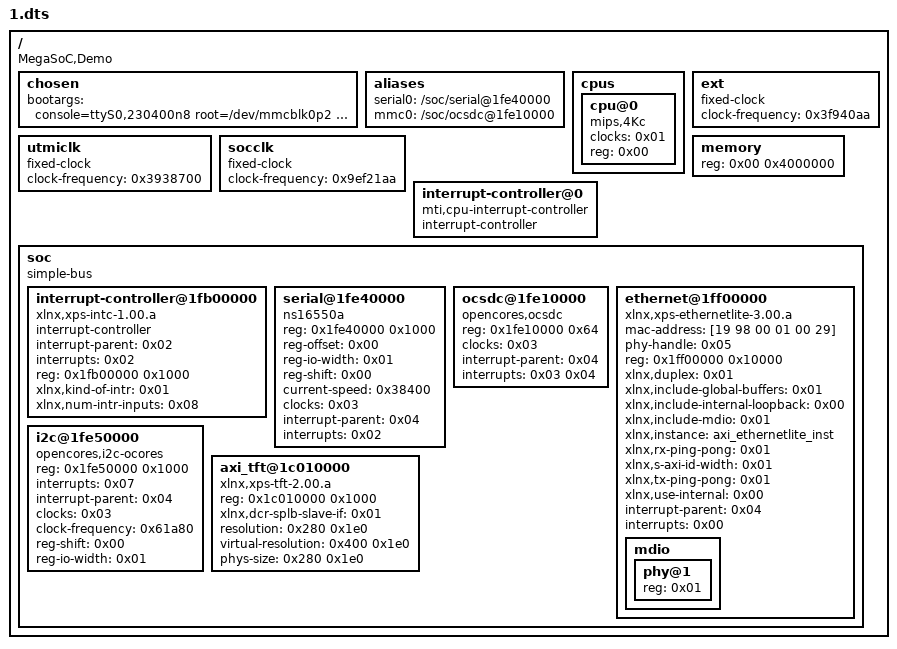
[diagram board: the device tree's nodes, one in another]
/dts-v1/;

/ {
	compatible = "MegaSoC,Demo";
	#address-cells = <0x01>;
	#size-cells = <0x01>;

	chosen {
		bootargs = "console=ttyS0,230400n8 root=/dev/mmcblk0p2 rootfstype=ext4 rw rootwait";
	};

	aliases {
		serial0 = "/soc/serial@1fe40000";
		mmc0 = "/soc/ocsdc@1fe10000";
	};

	cpus {
		#address-cells = <0x01>;
		#size-cells = <0x00>;

		cpu@0 {
			device_type = "cpu";
			compatible = "mips,4Kc";
			clocks = <0x01>;
			reg = <0x00>;
		};
	};

	ext {
		compatible = "fixed-clock";
		clock-frequency = <0x3f940aa>;
		#clock-cells = <0x00>;
		phandle = <0x01>;
	};

	utmiclk {
		compatible = "fixed-clock";
		clock-frequency = <0x3938700>;
		#clock-cells = <0x00>;
	};

	socclk {
		compatible = "fixed-clock";
		clock-frequency = <0x9ef21aa>;
		#clock-cells = <0x00>;
		phandle = <0x03>;
	};

	memory {
		device_type = "memory";
		reg = <0x00 0x4000000>;
	};

	interrupt-controller@0 {
		#address-cells = <0x00>;
		#interrupt-cells = <0x01>;
		interrupt-controller;
		compatible = "mti,cpu-interrupt-controller";
		phandle = <0x02>;
	};

	soc {
		compatible = "simple-bus";
		#address-cells = <0x01>;
		#size-cells = <0x01>;
		#interrupt-cells = <0x01>;
		ranges;

		interrupt-controller@1fb00000 {
			#interrupt-cells = <0x01>;
			compatible = "xlnx,xps-intc-1.00.a";
			interrupt-controller;
			interrupt-parent = <0x02>;
			interrupts = <0x02>;
			reg = <0x1fb00000 0x1000>;
			xlnx,kind-of-intr = <0x01>;
			xlnx,num-intr-inputs = <0x08>;
			phandle = <0x04>;
		};

		serial@1fe40000 {
			device_type = "serial";
			compatible = "ns16550a";
			reg = <0x1fe40000 0x1000>;
			reg-offset = <0x00>;
			reg-io-width = <0x01>;
			reg-shift = <0x00>;
			current-speed = <0x38400>;
			clocks = <0x03>;
			interrupt-parent = <0x04>;
			interrupts = <0x02>;
		};

		ocsdc@1fe10000 {
			compatible = "opencores,ocsdc";
			reg = <0x1fe10000 0x64>;
			clocks = <0x03>;
			interrupt-parent = <0x04>;
			interrupts = <0x03 0x04>;
		};

		ethernet@1ff00000 {
			compatible = "xlnx,xps-ethernetlite-3.00.a";
			device_type = "network";
			mac-address = [19 98 00 01 00 29];
			phy-handle = <0x05>;
			reg = <0x1ff00000 0x10000>;
			xlnx,duplex = <0x01>;
			xlnx,include-global-buffers = <0x01>;
			xlnx,include-internal-loopback = <0x00>;
			xlnx,include-mdio = <0x01>;
			xlnx,instance = "axi_ethernetlite_inst";
			xlnx,rx-ping-pong = <0x01>;
			xlnx,s-axi-id-width = <0x01>;
			xlnx,tx-ping-pong = <0x01>;
			xlnx,use-internal = <0x00>;
			interrupt-parent = <0x04>;
			interrupts = <0x00>;

			mdio {
				#address-cells = <0x01>;
				#size-cells = <0x00>;

				phy@1 {
					device_type = "ethernet-phy";
					reg = <0x01>;
					phandle = <0x05>;
				};
			};
		};

		i2c@1fe50000 {
			compatible = "opencores,i2c-ocores";
			reg = <0x1fe50000 0x1000>;
			interrupts = <0x07>;
			interrupt-parent = <0x04>;
			clocks = <0x03>;
			clock-frequency = <0x61a80>;
			reg-shift = <0x00>;
			reg-io-width = <0x01>;
		};

		axi_tft@1c010000 {
			compatible = "xlnx,xps-tft-2.00.a";
			reg = <0x1c010000 0x1000>;
			xlnx,dcr-splb-slave-if = <0x01>;
			resolution = <0x280 0x1e0>;
			virtual-resolution = <0x400 0x1e0>;
			phys-size = <0x280 0x1e0>;
		};
	};
};
